# bao1x register map
Vendor: baochip; File version: 1.0
Registers are 32-bit, read-write, reset 0x0 unless marked. A register's access mark holds for its fields unless they carry their own. Offsets are from the block's base; [hi:lo] are bit positions; {n}, {i} and the like mark numbered series.

## IRQARRAY19
Base 0xE000F000
0x00 EV_SOFT — Software interrupt trigger register. ) Bits set to `1` will trigger an interrupt. Interrupts trigger on write, but the value will persist in the register, allowing software to determine if a software interrupt was triggered by reading back the register. Software is responsible for clearing the register to 0. Repeated `1` writes without clearing will still trigger an interrupt.
  [15:0] trigger
0x04 EV_EDGE_TRIGGERED — If a bit is set to 1, then the hardware trigger is edge-triggered
  [15:0] use_edge
0x08 EV_POLARITY — If a bit is set to 1, then the polarity is rising edge triggered; 0 is falling edge triggered. Bit is ignored if `edge_triggered` is 0.
  [15:0] rising
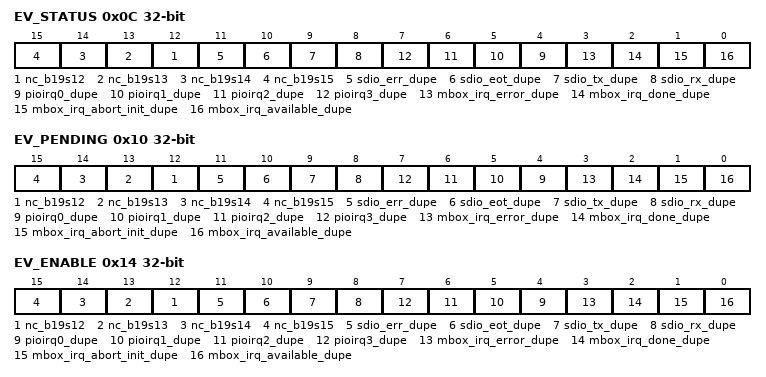
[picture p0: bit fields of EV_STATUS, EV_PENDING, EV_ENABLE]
0x0C EV_STATUS — `1` when a "nc_b19s15" event occurs. This event uses an `EventSourceFlex` form of triggering
  [n] nc_b19s{n} (n=12..15) — Level of the ``nc_b19s{n}`` event
  [11] sdio_err_dupe — Level of the ``sdio_err_dupe`` event
  [10] sdio_eot_dupe — Level of the ``sdio_eot_dupe`` event
  [9] sdio_tx_dupe — Level of the ``sdio_tx_dupe`` event
  [8] sdio_rx_dupe — Level of the ``sdio_rx_dupe`` event
  [n+4] pioirq{n}_dupe (n=0..3) — Level of the ``pioirq{n}_dupe`` event
  [3] mbox_irq_error_dupe — Level of the ``mbox_irq_error_dupe`` event
  [2] mbox_irq_done_dupe — Level of the ``mbox_irq_done_dupe`` event
  [1] mbox_irq_abort_init_dupe — Level of the ``mbox_irq_abort_init_dupe`` event
  [0] mbox_irq_available_dupe — Level of the ``mbox_irq_available_dupe`` event
0x10 EV_PENDING — `1` when a "nc_b19s15" event occurs. This event uses an `EventSourceFlex` form of triggering
  [n] nc_b19s{n} (n=12..15) — `1` when a "nc_b19s{n}" event occurs. This event uses an `EventSourceFlex` form of triggering
  [11] sdio_err_dupe — `1` when a "sdio_err_dupe" event occurs. This event uses an `EventSourceFlex` form of triggering
  [10] sdio_eot_dupe — `1` when a "sdio_eot_dupe" event occurs. This event uses an `EventSourceFlex` form of triggering
  [9] sdio_tx_dupe — `1` when a "sdio_tx_dupe" event occurs. This event uses an `EventSourceFlex` form of triggering
  [8] sdio_rx_dupe — `1` when a "sdio_rx_dupe" event occurs. This event uses an `EventSourceFlex` form of triggering
  [n+4] pioirq{n}_dupe (n=0..3) — `1` when a "pioirq{n}_dupe" event occurs. This event uses an `EventSourceFlex` form of triggering
  [3] mbox_irq_error_dupe — `1` when a "mbox_irq_error_dupe" event occurs. This event uses an `EventSourceFlex` form of triggering
  [2] mbox_irq_done_dupe — `1` when a "mbox_irq_done_dupe" event occurs. This event uses an `EventSourceFlex` form of triggering
  [1] mbox_irq_abort_init_dupe — `1` when a "mbox_irq_abort_init_dupe" event occurs. This event uses an `EventSourceFlex` form of triggering
  [0] mbox_irq_available_dupe — `1` when a "mbox_irq_available_dupe" event occurs. This event uses an `EventSourceFlex` form of triggering
0x14 EV_ENABLE — `1` when a "nc_b19s15" event occurs. This event uses an `EventSourceFlex` form of triggering
  [n] nc_b19s{n} (n=12..15) — Write a ``1`` to enable the ``nc_b19s{n}`` Event
  [11] sdio_err_dupe — Write a ``1`` to enable the ``sdio_err_dupe`` Event
  [10] sdio_eot_dupe — Write a ``1`` to enable the ``sdio_eot_dupe`` Event
  [9] sdio_tx_dupe — Write a ``1`` to enable the ``sdio_tx_dupe`` Event
  [8] sdio_rx_dupe — Write a ``1`` to enable the ``sdio_rx_dupe`` Event
  [n+4] pioirq{n}_dupe (n=0..3) — Write a ``1`` to enable the ``pioirq{n}_dupe`` Event
  [3] mbox_irq_error_dupe — Write a ``1`` to enable the ``mbox_irq_error_dupe`` Event
  [2] mbox_irq_done_dupe — Write a ``1`` to enable the ``mbox_irq_done_dupe`` Event
  [1] mbox_irq_abort_init_dupe — Write a ``1`` to enable the ``mbox_irq_abort_init_dupe`` Event
  [0] mbox_irq_available_dupe — Write a ``1`` to enable the ``mbox_irq_available_dupe`` Event
